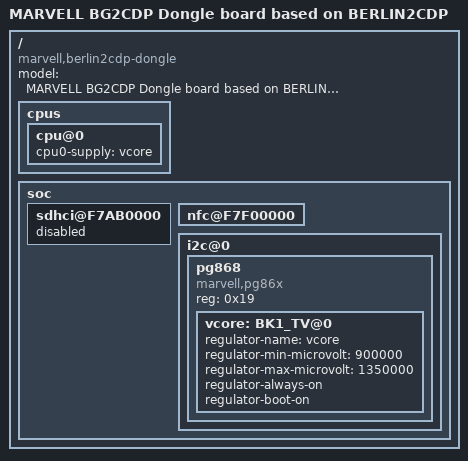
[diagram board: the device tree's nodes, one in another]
/*
 * MARVELL BERLIN2CDP Dongle board device tree source
 *
 * Author:	Jisheng Zhang <jszhang@marvell.com>
 * Copyright (c) 2013 Marvell International Ltd.
 *		http://www.marvell.com
 *
 * This program is free software; you can redistribute it and/or modify
 * it under the terms of the GNU General Public License version 2 as
 * published by the Free Software Foundation.
*/

/dts-v1/;
/include/ "berlin3cda0.dtsi"

/ {
	model = "MARVELL BG2CDP Dongle board based on BERLIN2CDP";
	compatible = "marvell,berlin2cdp-dongle", "marvell,berlin2cdp", "marvell,berlin";

	cpus {
		cpu@0 {
			cpu0-supply = <&vcore>;
		};
	};

	soc {
		sdhci@F7AB0000 {
			status = "disabled";
		};

		nfc@F7F00000 {
			status = "okay";
		};

		i2c@0 {
			pg868 {
				#address-cells = <1>;
				#size-cells = <0>;
				compatible = "marvell,pg86x";
				reg = <0x19>;
				vcore:BK1_TV@0 {
					regulator-name = "vcore";
					regulator-min-microvolt = <900000>;
					regulator-max-microvolt = <1350000>;
					regulator-always-on;
					regulator-boot-on;
				};
			};
		};
	};
};
